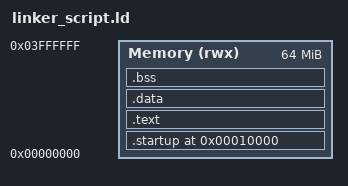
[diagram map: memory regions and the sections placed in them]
ENTRY(reset) 

MEMORY
{
	Memory (rwx):ORIGIN = 0x00000000 , LENGTH = 64M
}

SECTIONS
{	. = 0x10000; /* Here using the location counter (.) That  points to a specific section from specs this is the cpu entry point*/
	.startup . :  /* To specify a spefic  address to a specific section (put the startup at the entry point of the cpu) */
	{
		startup.o(.text)
	}> Memory
	.text :
	{
		*(.text) *(.rodata)
	}> Memory
	.data :
	{
		*(.data)	
	}> Memory
	.bss :
	{
		*(.bss)
	}> Memory
	. = . + 0x1000; /*The size of the Stack Memory */
	stack_top = . ; /* using label (symbol is just like variable but dosn't has a value only contain the address)*/
}																																																																																																																																																																																																																																																																																																																																																																																																																																																																																																																																																																																																																																																																																																																																																																																																																																																																																																																																																																																																																																																																																																																																																																																																																																																																																																																																																																																																																																																																																																																																																																																																																																																																																																																																																																																																																																																																																																																																																																																																																																																																																																																																																																																																																																																																																																																																																																																																																																																																																																																																																																																																																																																																																																																																																																																																																																																																																																																																																																																																																																																																																																																																																																																																																																																																																																																																																																																																																																																																																																																																																																																																																																																																																																																																																																																																																																																																																																																																																																																																																																																																																																																																																																																																																																																																																																																																																																																																																																																																																																																																																																																																																																																																																																																																																																																																																																																																																																																																																																																																																																																																																																																																																																																																																																																																																																																																																																																																																																																																																																																																																																																																																																																																																																																																																																																																																																																																																																																																																																																																																																																																																																																																																																																																																																																																																																																																																																																																																																																																																																																																																																																																																																																																																																									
